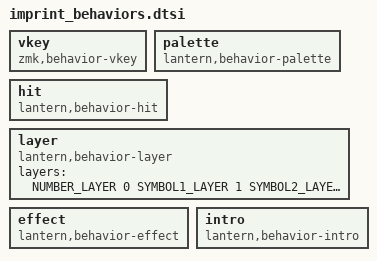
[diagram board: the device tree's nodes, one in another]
// Included in the keymap's behaviors { } node.

    HOLD_TAP_HP200(ime_kana, &kana)
    HOLD_TAP_HP200(ime_eiji, &eiji)

    #include "letter_morphs.dtsi"
    #include "arrow_behaviors.dtsi"

    // &vkey <id>: vendor HID report 0x20 (press = id, release = 0) that the
    // host bridge chord maps to an action. The behavior comes from
    // patches/zmk/vkey-report.patch (central builds only, USB only);
    // scripts/gen-vkey-aliases.py reads the ids from imprint.keymap.
    vkey: vkey {
        compatible = "zmk,behavior-vkey";
        #binding-cells = <1>;
    };

    // &palette: zmk-lantern's palette behavior (config/west.yml; its
    // src/palette.c), never on a key. The Imprint Dongle's code invokes it
    // with the colours `scripts/dongle.py palette` sends, and ZMK's split
    // transport carries the invocation to both halves by this node's name,
    // so the node is the same on all three (the keymap's behaviors reach
    // every imprint target); a half stores the six colours and paints its
    // key LEDs with slot 0 (CLAUDE.md, Invariants; the glossary: palette).
    palette: palette {
        compatible = "lantern,behavior-palette";
        #binding-cells = <2>;
    };

    // &hit: zmk-lantern's hit behavior (its src/hit.c), never on a key. The
    // Imprint Dongle sends it to a half with each key press of the other
    // half (param1 = the key position), and ZMK's split transport carries it
    // by this node's name, so the node is the same on all three, as &palette;
    // a half notes the press as a hit for the effects that cross the split
    // (zmk-lantern's crossing ring; t-6ttk). The dongle sends only to a half
    // whose link is at peripheral latency 0, the one USB powers (the
    // module's src/latency.c): a half on battery is dark and gets nothing.
    hit: hit {
        compatible = "lantern,behavior-hit";
        #binding-cells = <2>;
    };

    // &layer: zmk-lantern's layer behavior (its src/layer.c), never on a key.
    // The Imprint Dongle, where the keymap runs, sends a half which keys the
    // held layer binds to something of its own and the palette slot of its
    // colour, for the layer keys (t-6ttk), by this node's name, as &hit, and
    // only to a half at peripheral latency 0. layers pairs each layer shown
    // with its slot (t-6ttk's research, 5-6, the recommendation): Number 0,
    // Symbol 1 1, Symbol 2 3 (the same keys as Symbol 1, told apart by
    // colour), Function 4, Vkey LL and LM 1, Vkey RM and RR 3; the four arrow
    // layers are left out, since an arrow key's hold-tap raises its layer for
    // the length of a mere tap. Only the dongle reads the pairs.
    layer: layer {
        compatible = "lantern,behavior-layer";
        #binding-cells = <2>;
        layers = <NUMBER_LAYER 0  SYMBOL1_LAYER 1  SYMBOL2_LAYER 3  FUNCTION_LAYER 4
                  T_LL_LAYER 1  T_LM_LAYER 1  T_RM_LAYER 3  T_RR_LAYER 3>;
    };

    // &effect: zmk-lantern's effect behavior (its src/effect.c), never on a
    // key. The Imprint Dongle's code invokes it with the pick
    // `scripts/dongle.py effect` sends (param1 = a mask of the module's
    // effect bits, src/effect.h), and ZMK's split transport carries it to
    // both halves by this node's name, as &palette; each half stores the pick
    // and draws the picked effects its image builds (the halves' confs build
    // eight), the dongle stores it and resends it with the palette (CLAUDE.md,
    // Invariants; the glossary: effect).
    effect: effect {
        compatible = "lantern,behavior-effect";
        #binding-cells = <2>;
    };

    // &intro: zmk-lantern's intro behavior (its src/intro.c), never on a
    // key. The Imprint Dongle's code invokes it with the pick
    // `scripts/dongle.py intro` sends (param1 = one of the module's intro
    // bits, src/intro.h), and ZMK's split transport carries it to both
    // halves by this node's name, as &effect; each half stores the pick and
    // plays the picked intro its image builds as the boot light (the halves'
    // confs build the bands and the star waves), the dongle stores it and
    // resends it with the palette and the effect (CLAUDE.md, Invariants; the
    // glossary: intro).
    intro: intro {
        compatible = "lantern,behavior-intro";
        #binding-cells = <2>;
    };
